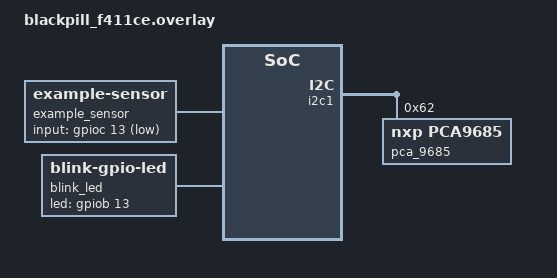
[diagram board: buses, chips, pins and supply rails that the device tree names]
/ {
	chosen {
		zephyr,selected_adc = &pca_9685;
	};

	example_sensor: example-sensor {
		compatible = "zephyr,example-sensor";
		input-gpios = <&gpioc 13 (GPIO_PULL_UP | GPIO_ACTIVE_LOW)>;
	};

	blink_led: blink-led {
		compatible = "blink-gpio-led";
		led-gpios = <&gpiob 13 GPIO_ACTIVE_HIGH>;
		blink-period-ms = <1000>;
	};
};

&i2c1 {
	status = "okay";

	pca_9685: pca9685@62 {
		compatible = "nxp,pca9685";
		reg = <0x62>;
	};
};
